VERSION ""

NS_ :

BS_:

BU_:
VAL_TABLE_ Brake_1 1 "1" 0 "0" ;
VAL_TABLE_ Regen_Mode 2 "03" 1 "02" 0 "01" ;
VAL_TABLE_ MCU_N_FaultGrade 3 "Grade 3" 2 "Grade 2" 1 "Grade 1" 0 "No fault" ;
VAL_TABLE_ Drive_Mode_Status 5 "Reserved" 4 "P" 3 "E" 2 "R" 1 "T" 0 "N" ;
VAL_TABLE_ MCU_VCU_Fault_Table 1 "fault" 0 "normal" ;
VAL_TABLE_ MCU_VCU_WorkStatus_PWM_Sts 1 "PWM on" 0 "PWM off" ;
VAL_TABLE_ MCU_VCU_WorkStatus_Ctrl_Mode 1 "Speed mode" 0 "Torque mode" ;
VAL_TABLE_ MCU_VCU_WorkStatus_Ready 1 "Ready" 0 "Not Ready" ;
VAL_TABLE_ MCU_VCU_WorkStatus_Fault_Table 1 "fault" 0 "no fault" ;
VAL_TABLE_ MCU_VCU_WorkStatus_Drive_Table 1 "Description for the value '0x1'" 0 "brake" ;
VAL_TABLE_ MCU_VCU_WorkStatus_Direction 1 "motor forward" 0 "motor reverse" ;
VAL_TABLE_ MCU_VCU_WorkStatus_Dischg_Table 1 "active discharge on" 0 "active discharge off" ;
VAL_TABLE_ MCU_VCU_WorkStatus_Halt_Table 1 "start" 0 "halt" ;
VAL_TABLE_ MCU_VCU_Main_Contactor_Table 1 "main contactor on" 0 "main contactor off" ;
VAL_TABLE_ MCU_VCU_Precharge_Table 1 "precharge on" 0 "precharge off" ;
VAL_TABLE_ MCU_VCU_Gear_Table 3 "Brake" 2 "R" 1 "D" 0 "N" ;
VAL_TABLE_ VCU_MCU_HVCircuit_Table 3 "Precharge to main contactor" 2 "main contactor off" 1 "main contactor on" 0 "precharge" ;
VAL_TABLE_ VCU_MCU_Discharge_Table 1 "start" 0 "forbidden" ;
VAL_TABLE_ VCU_MCU_Enable_Table 1 "enable" 0 "disable" ;
VAL_TABLE_ VCU_MCU_Control_Mode_Table 1 "speed" 0 "torque" ;
VAL_TABLE_ VCU_MCU_Valid_Invalid_Table 1 "valid" 0 "invalid" ;

BO_ 3221225472 VECTOR__INDEPENDENT_SIG_MSG: 0 Vector__XXX
 SG_ Brake_per : 0|8@1+ (1,0) [0|255] "" Vector__XXX
 SG_ Regen_Torque : 0|8@1+ (1,0) [0|255] "" Vector__XXX
 SG_ Current_Mode : 0|8@1+ (1,0) [0|255] "" Vector__XXX
 SG_ Vehicle_Mode : 0|8@1+ (1,0) [0|0] "" Vector__XXX
 SG_ Hill_hoald_Enable : 0|8@1+ (1,0) [0|255] "" Vector__XXX
 SG_ Throttle_ADC_value : 0|16@1+ (1,0) [0|65535] "" Vector__XXX
 SG_ MCU_F_RESERVE : 0|2@1+ (1,0) [0|0] "" Vector__XXX
 SG_ MCU_ContactorStatus_Main : 0|1@1+ (1,0) [0|0] "" Vector__XXX
 SG_ MCU_Gear : 0|2@1+ (1,0) [0|0] "" Vector__XXX
 SG_ MCU_ContactorStatus_Precharge : 0|1@1+ (1,0) [0|0] "" Vector__XXX
 SG_ MCU_N_FaultGrade : 0|4@1+ (1,0) [0|0] "" Vector__XXX

BO_ 337 Regn_Profile_Selection: 8 Vector__XXX
 SG_ Rgen_Profile_Selection : 0|8@1+ (1,0) [0|255] "" Vector__XXX

BO_ 1808 MCU_VCU_710: 8 Vector__XXX
 SG_ Throttle_Pot_Value : 24|8@1+ (0.1,0) [0|5] "V" Vector__XXX
 SG_ Throttle_Input_Command : 0|8@1+ (1,0) [0|100] "%" Vector__XXX

BO_ 1798 MCU_VCU_706: 1 Vector__XXX

BO_ 1830 MCU_VCU_726: 8 Vector__XXX
 SG_ Firmware_Version : 32|32@1+ (1,0) [0|0] "" Vector__XXX
 SG_ Configuration_Version : 0|32@1+ (1,0) [0|0] "" Vector__XXX

BO_ 1829 MCU_VCU_725: 2 Vector__XXX
 SG_ Inputs_Brake_Pot : 8|8@1+ (0.1,0) [0|0] "V" Vector__XXX
 SG_ Inputs_Brake_Command : 0|8@1+ (1,0) [0|0] "%" Vector__XXX

BO_ 2349508592 MCU_VCU_C0AA7F0: 8 Vector__XXX
 SG_ MCU_Brake_Sts : 54|1@1+ (1,0) [0|1] "" Vector__XXX
 SG_ MCU_N_FaultGrade : 52|2@1+ (1,0) [0|3] "" Vector__XXX
 SG_ MCU_N_FaultNUM : 56|8@1+ (1,0) [0|255] "" Vector__XXX
 SG_ MCU_F_RESERVE9 : 50|2@1+ (1,0) [0|0] "" Vector__XXX
 SG_ MCU_F_IGBT_HOC_WARNING : 49|1@1+ (1,0) [0|0] "" Vector__XXX
 SG_ MCU_F_ACC_UV_WARNING : 48|1@1+ (1,0) [0|0] "" Vector__XXX
 SG_ MCU_F_RESERVE8 : 47|1@1+ (1,0) [0|0] "" Vector__XXX
 SG_ MCU_F_MOTOR_TEMP_SENSOR : 46|1@1+ (1,0) [0|0] "" Vector__XXX
 SG_ MCU_F_IGBT_TEMP_SENSOR : 45|1@1+ (1,0) [0|0] "" Vector__XXX
 SG_ MCU_F_H_W_OC : 44|1@1+ (1,0) [0|0] "" Vector__XXX
 SG_ MCU_F_H_V_OC : 43|1@1+ (1,0) [0|0] "" Vector__XXX
 SG_ MCU_F_H_U_OC : 42|1@1+ (1,0) [0|0] "" Vector__XXX
 SG_ MCU_F_RESERVE7 : 41|1@1+ (1,0) [0|0] "" Vector__XXX
 SG_ MCU_F_W_DOWN_IGBT : 40|1@1+ (1,0) [0|0] "" Vector__XXX
 SG_ MCU_F_W_UP_IGBT : 39|1@1+ (1,0) [0|0] "" Vector__XXX
 SG_ MCU_F_V_DOWN_IGBT : 38|1@1+ (1,0) [0|0] "" Vector__XXX
 SG_ MCU_F_V_UP_IGBT : 37|1@1+ (1,0) [0|0] "" Vector__XXX
 SG_ MCU_F_U_DOWN_IGBT : 36|1@1+ (1,0) [0|0] "" Vector__XXX
 SG_ MCU_F_U_UP_IGBT : 35|1@1+ (1,0) [0|0] "" Vector__XXX
 SG_ MCU_F_RESERVE6 : 31|4@1+ (1,0) [0|0] "" Vector__XXX
 SG_ MCU_F_MOTOR_OT_H : 30|1@1+ (1,0) [0|0] "" Vector__XXX
 SG_ MCU_F_MOTOR_OT_L : 29|1@1+ (1,0) [0|0] "" Vector__XXX
 SG_ MCU_F_RESERVE5 : 25|4@1+ (1,0) [0|0] "" Vector__XXX
 SG_ MCU_F_IGBT_OT_H : 24|1@1+ (1,0) [0|0] "" Vector__XXX
 SG_ MCU_F_IGBT_OT_L : 23|1@1+ (1,0) [0|0] "" Vector__XXX
 SG_ MCU_F_CAN_OFFLINE : 22|1@1+ (1,0) [0|0] "" Vector__XXX
 SG_ MCU_F_SPEED_OV : 21|1@1+ (1,0) [0|0] "" Vector__XXX
 SG_ MCU_F_RESERVE4 : 19|2@1+ (1,0) [0|0] "" Vector__XXX
 SG_ MCU_F_CONTROL_OL_H : 18|1@1+ (1,0) [0|0] "" Vector__XXX
 SG_ MCU_F_CONTROL_OL_L : 17|1@1+ (1,0) [0|0] "" Vector__XXX
 SG_ MCU_F_BUS_OV_H : 16|1@1+ (1,0) [0|0] "" Vector__XXX
 SG_ MCU_F_BUS_OV_L : 15|1@1+ (1,0) [0|0] "" Vector__XXX
 SG_ MCU_F_BUS_UV_H : 14|1@1+ (1,0) [0|0] "" Vector__XXX
 SG_ MCU_F_BUS_UV_L : 13|1@1+ (1,0) [0|0] "" Vector__XXX
 SG_ MCU_F_S_OC : 12|1@1+ (1,0) [0|0] "" Vector__XXX
 SG_ MCU_F_ACC_UV : 11|1@1+ (1,0) [0|0] "" Vector__XXX
 SG_ MCU_F_GUN_SELF : 10|1@1+ (1,0) [0|0] "" Vector__XXX
 SG_ MCU_F_RESERVE3 : 8|2@1+ (1,0) [0|0] "" Vector__XXX
 SG_ MCU_F_CURRENT_DETECT : 7|1@1+ (1,0) [0|0] "" Vector__XXX
 SG_ MCU_F_LACK_PHASE : 6|1@1+ (1,0) [0|0] "" Vector__XXX
 SG_ MCU_F_ENCORDE : 5|1@1+ (1,0) [0|0] "" Vector__XXX
 SG_ MCU_F_RESERVE2 : 4|1@1+ (1,0) [0|0] "" Vector__XXX
 SG_ MCU_F_H_OV : 3|1@1+ (1,0) [0|0] "" Vector__XXX
 SG_ MCU_F_RESERVE1 : 2|1@1+ (1,0) [0|0] "" Vector__XXX
 SG_ MCU_F_H_OC : 1|1@1+ (1,0) [0|0] "" Vector__XXX
 SG_ MCU_F_IGBT : 0|1@1+ (1,0) [0|0] "" Vector__XXX

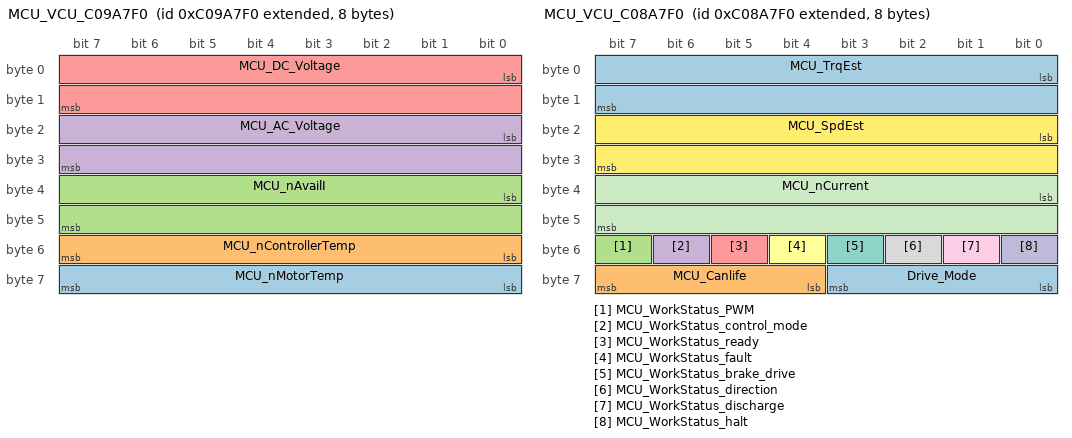
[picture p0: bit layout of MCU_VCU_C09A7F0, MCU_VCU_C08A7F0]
BO_ 2349443056 MCU_VCU_C09A7F0: 8 Vector__XXX
 SG_ MCU_nMotorTemp : 56|8@1+ (1,-40) [0|0] "°C" Vector__XXX
 SG_ MCU_nControllerTemp : 48|8@1+ (1,-40) [0|0] "°C" Vector__XXX
 SG_ MCU_nAvailI : 32|16@1+ (0.1,-3200) [0|6553.5] "A" Vector__XXX
 SG_ MCU_AC_Voltage : 16|16@1+ (0.1,0) [0|0] "V" Vector__XXX
 SG_ MCU_DC_Voltage : 0|16@1+ (0.1,0) [0|0] "V" Vector__XXX

BO_ 2349377520 MCU_VCU_C08A7F0: 8 Vector__XXX
 SG_ Drive_Mode : 56|4@1+ (1,0) [0|0] "" Vector__XXX
 SG_ MCU_Canlife : 60|4@1+ (1,0) [0|0] "" Vector__XXX
 SG_ MCU_WorkStatus_PWM : 55|1@1+ (1,0) [0|0] "" Vector__XXX
 SG_ MCU_WorkStatus_control_mode : 54|1@1+ (1,0) [0|0] "" Vector__XXX
 SG_ MCU_WorkStatus_ready : 53|1@1+ (1,0) [0|0] "" Vector__XXX
 SG_ MCU_WorkStatus_fault : 52|1@1+ (1,0) [0|0] "" Vector__XXX
 SG_ MCU_WorkStatus_brake_drive : 51|1@1+ (1,0) [0|0] "" Vector__XXX
 SG_ MCU_WorkStatus_direction : 50|1@1+ (1,0) [0|0] "" Vector__XXX
 SG_ MCU_WorkStatus_discharge : 49|1@1+ (1,0) [0|0] "" Vector__XXX
 SG_ MCU_WorkStatus_halt : 48|1@1+ (1,0) [0|0] "" Vector__XXX
 SG_ MCU_nCurrent : 32|16@1+ (0.1,-3200) [0|0] "A" Vector__XXX
 SG_ MCU_SpdEst : 16|16@1+ (1,-32000) [0|0] "rpm" Vector__XXX
 SG_ MCU_TrqEst : 0|16@1+ (0.1,-3200) [0|0] "Nm" Vector__XXX

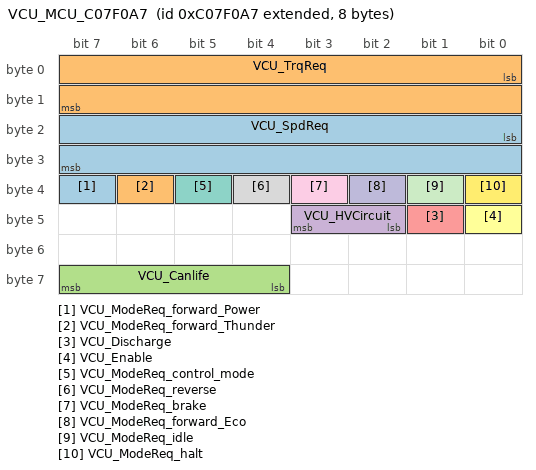
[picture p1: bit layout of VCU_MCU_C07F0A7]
BO_ 2349330599 VCU_MCU_C07F0A7: 8 Vector__XXX
 SG_ VCU_ModeReq_forward_Power : 39|1@1+ (1,0) [0|0] "" Vector__XXX
 SG_ VCU_ModeReq_forward_Thunder : 38|1@1+ (1,0) [0|0] "" Vector__XXX
 SG_ VCU_Canlife : 60|4@1+ (1,0) [0|0] "" Vector__XXX
 SG_ VCU_HVCircuit : 42|2@1+ (1,0) [0|0] "" Vector__XXX
 SG_ VCU_Discharge : 41|1@1+ (1,0) [0|0] "" Vector__XXX
 SG_ VCU_Enable : 40|1@1+ (1,0) [0|0] "" Vector__XXX
 SG_ VCU_ModeReq_control_mode : 37|1@1+ (1,0) [0|0] "" Vector__XXX
 SG_ VCU_ModeReq_reverse : 36|1@1+ (1,0) [0|0] "" Vector__XXX
 SG_ VCU_ModeReq_brake : 35|1@1+ (1,0) [0|0] "" Vector__XXX
 SG_ VCU_ModeReq_forward_Eco : 34|1@1+ (1,0) [0|0] "" Vector__XXX
 SG_ VCU_ModeReq_idle : 33|1@1+ (1,0) [0|0] "" Vector__XXX
 SG_ VCU_ModeReq_halt : 32|1@1+ (1,0) [0|0] "" Vector__XXX
 SG_ VCU_SpdReq : 16|16@1+ (1,-32000) [0|0] "rpm" Vector__XXX
 SG_ VCU_TrqReq : 0|16@1+ (0.1,-3200) [0|0] "Nm" Vector__XXX

BO_ 265 BMS_MCU_109: 2 Vector__XXX
 SG_ BMS_Soc : 0|16@1+ (0.01,0) [0|0] "%" Vector__XXX

BO_ 272 BMS_MCU_110: 4 Vector__XXX
 SG_ battery_current : 32|32@1- (1e-05,0) [-21474836.48|21474836.47] "A" Vector__XXX

BO_ 298 BMS_MCU_12A: 8 Vector__XXX
 SG_ BMS_DC_Disharge_Rrquest : 16|16@1+ (0.1,0) [0|0] "A" Vector__XXX
 SG_ BMS_DC_Charge_Rrquest : 0|16@1+ (0.1,0) [0|0] "A" Vector__XXX

CM_ BO_ 3221225472 "This is a message for not used signals, created by Vector CANdb++ DBC OLE DB Provider.";
CM_ SG_ 3221225472 MCU_F_RESERVE "预留4";
CM_ SG_ 3221225472 MCU_ContactorStatus_Main "主接触器状态";
CM_ SG_ 3221225472 MCU_Gear "MCU当前档位";
CM_ SG_ 3221225472 MCU_ContactorStatus_Precharge "预充接触器状态";
CM_ SG_ 3221225472 MCU_N_FaultGrade "故障等级";
CM_ SG_ 1830 Firmware_Version "固件版本";
CM_ SG_ 1830 Configuration_Version "配置版本";
CM_ SG_ 1829 Inputs_Brake_Pot "刹车电压";
CM_ SG_ 1829 Inputs_Brake_Command "刹车百分比";
CM_ SG_ 2349508592 MCU_N_FaultNUM "故障个数";
CM_ SG_ 2349508592 MCU_F_RESERVE9 "预留9";
CM_ SG_ 2349508592 MCU_F_IGBT_HOC_WARNING "超速预警";
CM_ SG_ 2349508592 MCU_F_ACC_UV_WARNING "低压欠压预警";
CM_ SG_ 2349508592 MCU_F_RESERVE8 "预留8";
CM_ SG_ 2349508592 MCU_F_MOTOR_TEMP_SENSOR "电机温度传感器故障";
CM_ SG_ 2349508592 MCU_F_IGBT_TEMP_SENSOR "IGBT温度传感器故障";
CM_ SG_ 2349508592 MCU_F_H_W_OC "W相硬件过流故障";
CM_ SG_ 2349508592 MCU_F_H_V_OC "V相硬件过流故障";
CM_ SG_ 2349508592 MCU_F_H_U_OC "U相硬件过流故障";
CM_ SG_ 2349508592 MCU_F_RESERVE7 "预留7";
CM_ SG_ 2349508592 MCU_F_W_DOWN_IGBT "W相下桥IGBT故障";
CM_ SG_ 2349508592 MCU_F_W_UP_IGBT "W相上桥IGBT故障";
CM_ SG_ 2349508592 MCU_F_V_DOWN_IGBT "V相下桥IGBT故障";
CM_ SG_ 2349508592 MCU_F_V_UP_IGBT "V相上桥IGBT故障";
CM_ SG_ 2349508592 MCU_F_U_DOWN_IGBT "U相下桥IGBT故障";
CM_ SG_ 2349508592 MCU_F_U_UP_IGBT "U相上桥IGBT故障";
CM_ SG_ 2349508592 MCU_F_RESERVE6 "预留6";
CM_ SG_ 2349508592 MCU_F_MOTOR_OT_H "电机严重过温故障";
CM_ SG_ 2349508592 MCU_F_MOTOR_OT_L "电机一般过温故障";
CM_ SG_ 2349508592 MCU_F_RESERVE5 "预留5";
CM_ SG_ 2349508592 MCU_F_IGBT_OT_H "IGBT严重过温故障";
CM_ SG_ 2349508592 MCU_F_IGBT_OT_L "IGBT一般过温故障";
CM_ SG_ 2349508592 MCU_F_CAN_OFFLINE "总线超时故障";
CM_ SG_ 2349508592 MCU_F_SPEED_OV "超速故障";
CM_ SG_ 2349508592 MCU_F_RESERVE4 "预留4";
CM_ SG_ 2349508592 MCU_F_CONTROL_OL_H "控制器过载故障";
CM_ SG_ 2349508592 MCU_F_CONTROL_OL_L "控制器过载预警故障";
CM_ SG_ 2349508592 MCU_F_BUS_OV_H "严重过压故障";
CM_ SG_ 2349508592 MCU_F_BUS_OV_L "一般过压故障";
CM_ SG_ 2349508592 MCU_F_BUS_UV_H "严重欠压故障 ";
CM_ SG_ 2349508592 MCU_F_BUS_UV_L "一般欠压故障";
CM_ SG_ 2349508592 MCU_F_S_OC "软件过流故障";
CM_ SG_ 2349508592 MCU_F_ACC_UV "低压软件欠压故障";
CM_ SG_ 2349508592 MCU_F_GUN_SELF "油门自检故障";
CM_ SG_ 2349508592 MCU_F_RESERVE3 "预留3";
CM_ SG_ 2349508592 MCU_F_CURRENT_DETECT "电流检测故障";
CM_ SG_ 2349508592 MCU_F_LACK_PHASE "输出缺相故障";
CM_ SG_ 2349508592 MCU_F_ENCORDE "编码器故障";
CM_ SG_ 2349508592 MCU_F_RESERVE2 "预留2";
CM_ SG_ 2349508592 MCU_F_H_OV "母线硬件过压故障";
CM_ SG_ 2349508592 MCU_F_RESERVE1 "预留1";
CM_ SG_ 2349508592 MCU_F_H_OC "硬件过流故障";
CM_ SG_ 2349508592 MCU_F_IGBT "IGBT故障";
CM_ SG_ 2349443056 MCU_nMotorTemp "电机温度";
CM_ SG_ 2349443056 MCU_nControllerTemp "电机控制器温度";
CM_ SG_ 2349443056 MCU_nAvailI "交流有效值";
CM_ SG_ 2349443056 MCU_AC_Voltage "MCU交流电压";
CM_ SG_ 2349443056 MCU_DC_Voltage "MCU直流电压";
CM_ SG_ 2349377520 MCU_Canlife "MCU生命信号";
CM_ SG_ 2349377520 MCU_WorkStatus_PWM " MCU工作状态_PWM";
CM_ SG_ 2349377520 MCU_WorkStatus_control_mode "MCU工作状态_控制模式";
CM_ SG_ 2349377520 MCU_WorkStatus_ready "MCU工作状态_准备";
CM_ SG_ 2349377520 MCU_WorkStatus_fault "MCU工作状态_故障";
CM_ SG_ 2349377520 MCU_WorkStatus_brake_drive "MCU工作状态_刹车驱动";
CM_ SG_ 2349377520 MCU_WorkStatus_direction "MCU工作状态_电机方向";
CM_ SG_ 2349377520 MCU_WorkStatus_discharge "MCU工作状态_主动放电";
CM_ SG_ 2349377520 MCU_WorkStatus_halt "MCU工作状态_挂起";
CM_ SG_ 2349377520 MCU_nCurrent "直流母线电流";
CM_ SG_ 2349377520 MCU_SpdEst "电机实际转速";
CM_ SG_ 2349377520 MCU_TrqEst "电机输出扭矩";
CM_ SG_ 2349330599 VCU_Canlife "VCU生命信号";
CM_ SG_ 2349330599 VCU_HVCircuit "母线状态";
CM_ SG_ 2349330599 VCU_Discharge "主动放电命令";
CM_ SG_ 2349330599 VCU_Enable "使能信号";
CM_ SG_ 2349330599 VCU_ModeReq_control_mode "工作模式命令_控制模式";
CM_ SG_ 2349330599 VCU_ModeReq_reverse "工作模式命令_后退";
CM_ SG_ 2349330599 VCU_ModeReq_brake "工作模式命令_刹车";
CM_ SG_ 2349330599 VCU_ModeReq_forward_Eco "工作模式命令_前进";
CM_ SG_ 2349330599 VCU_ModeReq_idle "工作模式命令_空闲";
CM_ SG_ 2349330599 VCU_ModeReq_halt "工作模式命令_挂起";
CM_ SG_ 2349330599 VCU_SpdReq "转速命令";
CM_ SG_ 2349330599 VCU_TrqReq "扭矩命令";
CM_ SG_ 265 BMS_Soc "电池SOC";
CM_ SG_ 298 BMS_DC_Disharge_Rrquest "电池最大放电电流";
CM_ SG_ 298 BMS_DC_Charge_Rrquest "电池最大充电电流";
VAL_ 3221225472 Vehicle_Mode 5 "Reserved" 4 "P" 3 "E" 2 "R" 1 "T" 0 "N" ;
VAL_ 3221225472 MCU_ContactorStatus_Main 1 "main contactor on" 0 "main contactor off" ;
VAL_ 3221225472 MCU_Gear 3 "Brake" 2 "R" 1 "D" 0 "N" ;
VAL_ 3221225472 MCU_ContactorStatus_Precharge 1 "precharge on" 0 "precharge off" ;
VAL_ 2349508592 MCU_Brake_Sts 1 "1" 0 "0" ;
VAL_ 2349508592 MCU_N_FaultGrade 3 "Grade 3" 2 "Grade 2" 1 "Grade 1" 0 "No fault" ;
VAL_ 2349508592 MCU_F_IGBT_HOC_WARNING 1 "fault" 0 "normal" ;
VAL_ 2349508592 MCU_F_ACC_UV_WARNING 1 "fault" 0 "normal" ;
VAL_ 2349508592 MCU_F_MOTOR_TEMP_SENSOR 1 "fault" 0 "normal" ;
VAL_ 2349508592 MCU_F_IGBT_TEMP_SENSOR 1 "fault" 0 "normal" ;
VAL_ 2349508592 MCU_F_H_W_OC 1 "fault" 0 "normal" ;
VAL_ 2349508592 MCU_F_H_V_OC 1 "fault" 0 "normal" ;
VAL_ 2349508592 MCU_F_H_U_OC 1 "fault" 0 "normal" ;
VAL_ 2349508592 MCU_F_W_DOWN_IGBT 1 "fault" 0 "normal" ;
VAL_ 2349508592 MCU_F_W_UP_IGBT 1 "fault" 0 "normal" ;
VAL_ 2349508592 MCU_F_V_DOWN_IGBT 1 "fault" 0 "normal" ;
VAL_ 2349508592 MCU_F_V_UP_IGBT 1 "fault" 0 "normal" ;
VAL_ 2349508592 MCU_F_U_DOWN_IGBT 1 "fault" 0 "normal" ;
VAL_ 2349508592 MCU_F_U_UP_IGBT 1 "fault" 0 "normal" ;
VAL_ 2349508592 MCU_F_MOTOR_OT_H 1 "fault" 0 "normal" ;
VAL_ 2349508592 MCU_F_MOTOR_OT_L 1 "fault" 0 "normal" ;
VAL_ 2349508592 MCU_F_IGBT_OT_H 1 "fault" 0 "normal" ;
VAL_ 2349508592 MCU_F_IGBT_OT_L 1 "fault" 0 "normal" ;
VAL_ 2349508592 MCU_F_CAN_OFFLINE 1 "fault" 0 "normal" ;
VAL_ 2349508592 MCU_F_SPEED_OV 1 "fault" 0 "normal" ;
VAL_ 2349508592 MCU_F_CONTROL_OL_H 1 "fault" 0 "normal" ;
VAL_ 2349508592 MCU_F_CONTROL_OL_L 1 "fault" 0 "normal" ;
VAL_ 2349508592 MCU_F_BUS_OV_H 1 "fault" 0 "normal" ;
VAL_ 2349508592 MCU_F_BUS_OV_L 1 "fault" 0 "normal" ;
VAL_ 2349508592 MCU_F_BUS_UV_H 1 "fault" 0 "normal" ;
VAL_ 2349508592 MCU_F_BUS_UV_L 1 "fault" 0 "normal" ;
VAL_ 2349508592 MCU_F_S_OC 1 "fault" 0 "normal" ;
VAL_ 2349508592 MCU_F_ACC_UV 1 "fault" 0 "normal" ;
VAL_ 2349508592 MCU_F_GUN_SELF 1 "fault" 0 "normal" ;
VAL_ 2349508592 MCU_F_CURRENT_DETECT 1 "fault" 0 "normal" ;
VAL_ 2349508592 MCU_F_LACK_PHASE 1 "fault" 0 "normal" ;
VAL_ 2349508592 MCU_F_ENCORDE 1 "fault" 0 "normal" ;
VAL_ 2349508592 MCU_F_H_OV 1 "fault" 0 "normal" ;
VAL_ 2349508592 MCU_F_H_OC 1 "fault" 0 "normal" ;
VAL_ 2349508592 MCU_F_IGBT 1 "fault" 0 "normal" ;
VAL_ 2349377520 Drive_Mode 5 "Reserved" 4 "P" 3 "E" 2 "R" 1 "T" 0 "N" ;
VAL_ 2349377520 MCU_WorkStatus_PWM 1 "PWM on" 0 "PWM off" ;
VAL_ 2349377520 MCU_WorkStatus_control_mode 1 "Speed mode" 0 "Torque mode" ;
VAL_ 2349377520 MCU_WorkStatus_ready 1 "Ready" 0 "Not Ready" ;
VAL_ 2349377520 MCU_WorkStatus_fault 1 "fault" 0 "no fault" ;
VAL_ 2349377520 MCU_WorkStatus_brake_drive 1 "Description for the value '0x1'" 0 "brake" ;
VAL_ 2349377520 MCU_WorkStatus_direction 1 "motor forward" 0 "motor reverse" ;
VAL_ 2349377520 MCU_WorkStatus_discharge 1 "active discharge on" 0 "active discharge off" ;
VAL_ 2349377520 MCU_WorkStatus_halt 1 "start" 0 "halt" ;
VAL_ 2349330599 VCU_ModeReq_forward_Power 1 "valid" 0 "invalid" ;
VAL_ 2349330599 VCU_ModeReq_forward_Thunder 1 "valid" 0 "invalid" ;
VAL_ 2349330599 VCU_HVCircuit 3 "Precharge to main contactor" 2 "main contactor off" 1 "main contactor on" 0 "precharge" ;
VAL_ 2349330599 VCU_Discharge 1 "start" 0 "forbidden" ;
VAL_ 2349330599 VCU_Enable 1 "enable" 0 "disable" ;
VAL_ 2349330599 VCU_ModeReq_control_mode 1 "speed" 0 "torque" ;
VAL_ 2349330599 VCU_ModeReq_reverse 1 "valid" 0 "invalid" ;
VAL_ 2349330599 VCU_ModeReq_brake 1 "valid" 0 "invalid" ;
VAL_ 2349330599 VCU_ModeReq_forward_Eco 1 "valid" 0 "invalid" ;
VAL_ 2349330599 VCU_ModeReq_idle 1 "valid" 0 "invalid" ;
VAL_ 2349330599 VCU_ModeReq_halt 1 "valid" 0 "invalid" ;
